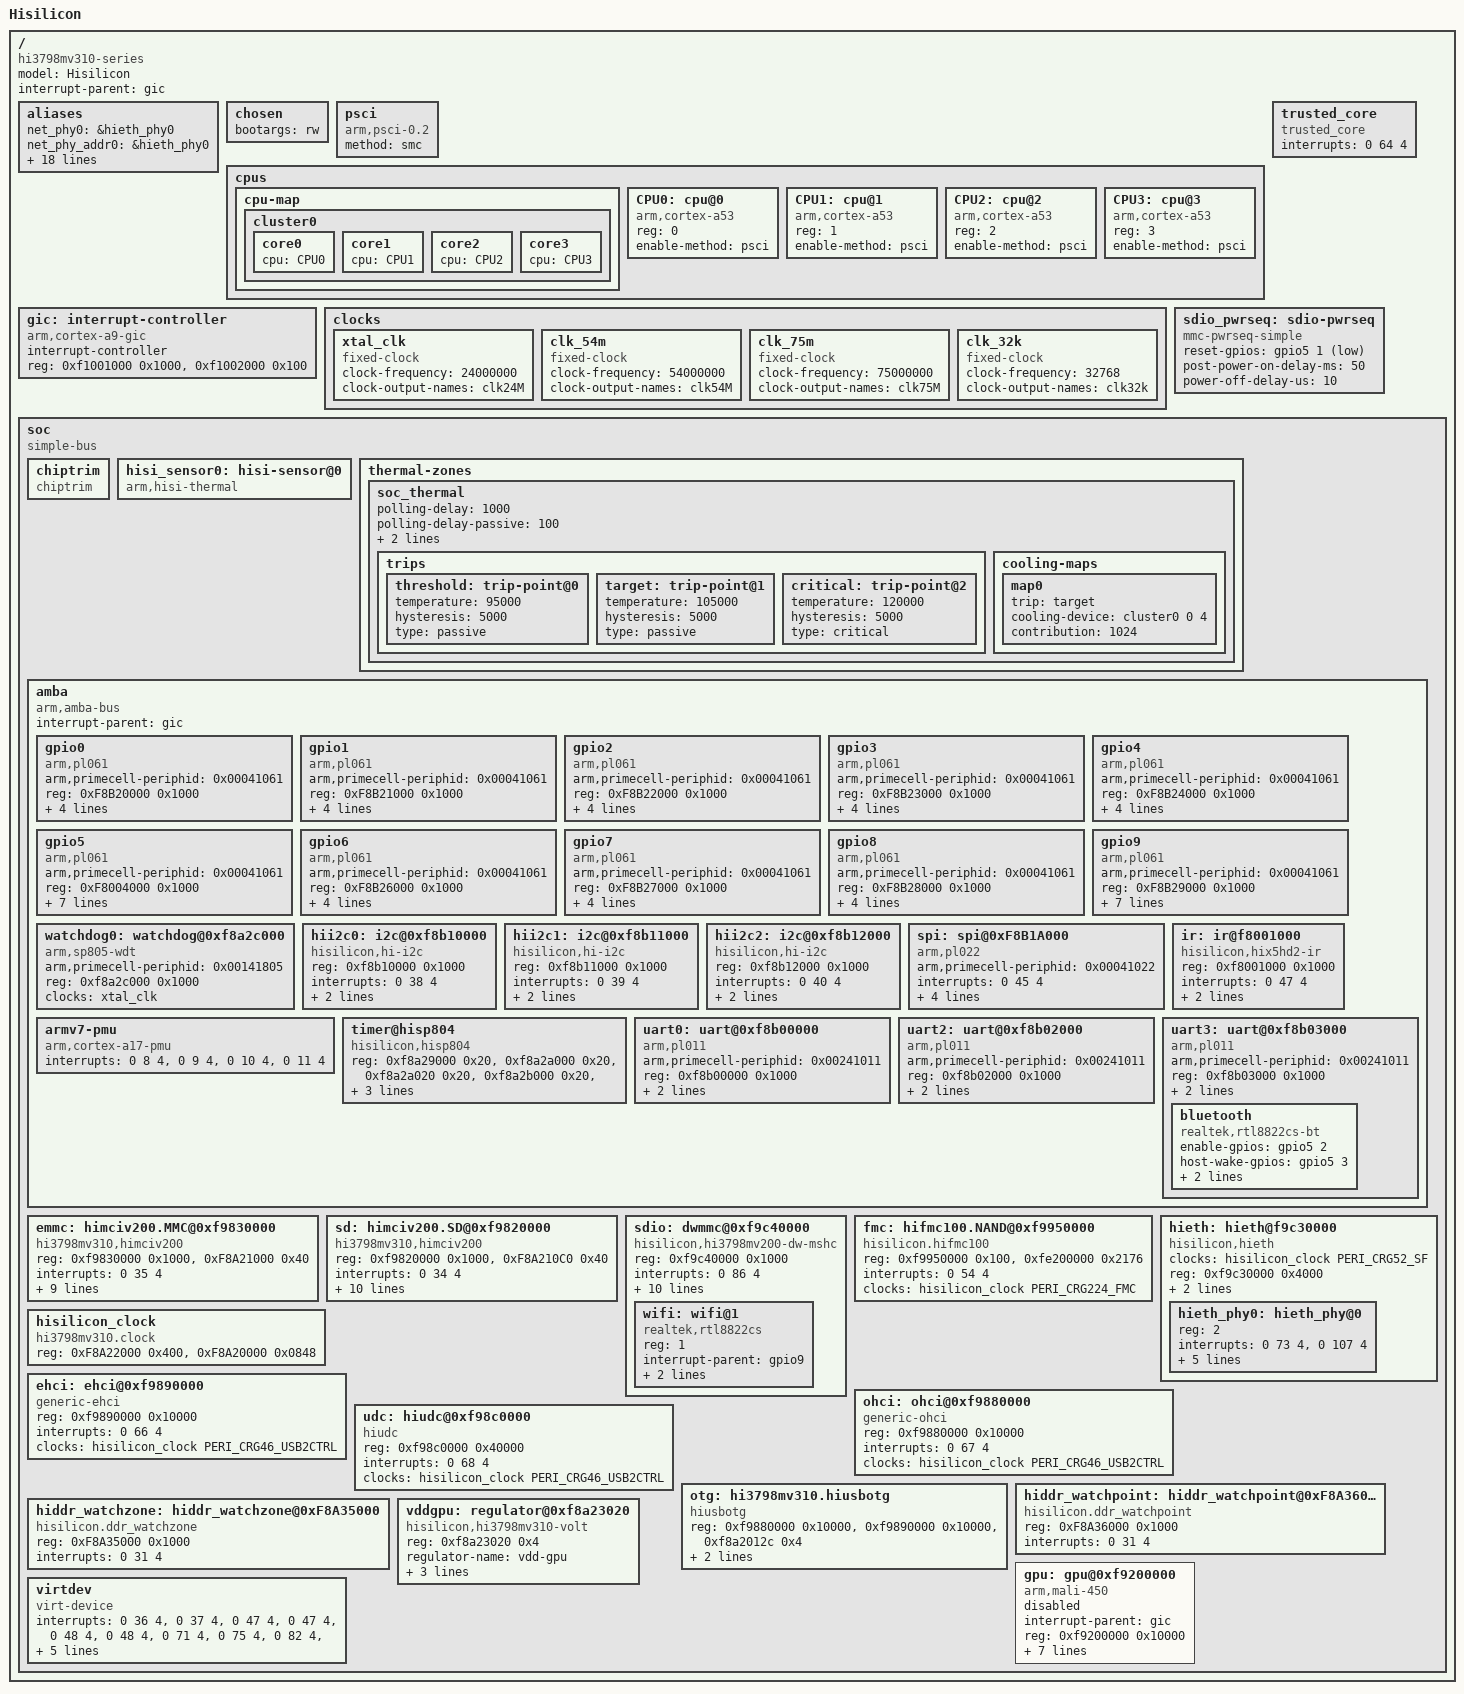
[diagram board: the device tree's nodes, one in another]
/dts-v1/;

#include <dt-bindings/clock/hi3798mv310-clock.h>
#include <dt-bindings/gpio/gpio.h>
#include <dt-bindings/interrupt-controller/irq.h>
#include <dt-bindings/interrupt-controller/arm-gic.h>

/ {
	model = "Hisilicon";
	compatible = "hi3798mv310-series";
	#address-cells = <1>;
	#size-cells = <1>;
	interrupt-parent = <&gic>;

	aliases {
		net_phy0 = &hieth_phy0;
		net_phy_addr0 = &hieth_phy0;
		emmc = &emmc;
		sd   = &sd;
		sdio = &sdio;
		ohci0= &ohci;
		ehci0= &ehci;
		uart0= &uart0;
		uart2= &uart2;
		uart3= &uart3;
		fmc  = &fmc;
		udc  = &udc;
		otg  = &otg;
		i2c0=&hii2c0;
		i2c1=&hii2c1;
		i2c2=&hii2c2;
		spi0=&spi;
		chiptrim=&chiptrim;
		wlan0 = &wifi;
		bluetooth0 = &bluetooth;
	};

	chosen {
		bootargs = "rw";
	};

	psci {
		compatible = "arm,psci-0.2";
		method = "smc";
	};

	cpus {
		#address-cells = <1>;
		#size-cells = <0>;
		#cooling-cells = <2>;

		cpu-map {
			cluster0: cluster0 {
				core0 { cpu = <&CPU0>; };
				core1 { cpu = <&CPU1>; };
				core2 { cpu = <&CPU2>; };
				core3 { cpu = <&CPU3>; };
			};
		};

		CPU0: cpu@0 {
			compatible = "arm,cortex-a53";
			device_type = "cpu";
			reg = <0>;
			enable-method = "psci";
		};
		CPU1: cpu@1 {
			compatible = "arm,cortex-a53";
			device_type = "cpu";
			reg = <1>;
			enable-method = "psci";
		};
		CPU2: cpu@2 {
			compatible = "arm,cortex-a53";
			device_type = "cpu";
			reg = <2>;
			enable-method = "psci";
		};
		CPU3: cpu@3 {
			compatible = "arm,cortex-a53";
			device_type = "cpu";
			reg = <3>;
			enable-method = "psci";
		};
	};

	gic: interrupt-controller {
		compatible = "arm,cortex-a9-gic";
		#interrupt-cells = <3>;
		#address-cells = <0>;
		interrupt-controller;
		reg = <0xf1001000 0x1000>, <0xf1002000 0x100>;
	};

	/* 固定时钟 */
	clocks {
		xtal_clk: xtal_clk {
			compatible = "fixed-clock";
			#clock-cells = <0>;
			clock-frequency = <24000000>;
			clock-output-names = "clk24M";
		};

		clk_54m: clk_54m{
			compatible = "fixed-clock";
			#clock-cells = <0>;
			clock-frequency = <54000000>;
			clock-output-names = "clk54M";
		};

		clk_75m: clk_75m{
			compatible = "fixed-clock";
			#clock-cells = <0>;
			clock-frequency = <75000000>;
			clock-output-names = "clk75M";
		};

		/* 6222B-SRC 低功耗时钟 - 引脚31 LPO, 32.768KHz */
		clk_32k: clk_32k {
			compatible = "fixed-clock";
			#clock-cells = <0>;
			clock-frequency = <32768>;
			clock-output-names = "clk32k";
		};
	};

	trusted_core {
		compatible = "trusted_core";
		interrupts = <0 64 4>;
	};

	/* 6222B-SRC WiFi 模块电源序列 - 控制 WL_REG_ON (gpio5_1) */
	sdio_pwrseq: sdio-pwrseq {
		compatible = "mmc-pwrseq-simple";
		/* WL_REG_ON - 引脚15, 高电平开启, 低电平关闭 */
		reset-gpios = <&gpio5 1 GPIO_ACTIVE_LOW>;
		/* 数据手册 Tchip Ready: 0-10ms, TSDIO Ready: 12ms, 取50ms确保稳定 */
		post-power-on-delay-ms = <50>;
		power-off-delay-us = <10>;
		status = "okay";
	};

	soc {
		#address-cells = <1>;
		#size-cells = <1>;
		compatible = "simple-bus";
		device_type = "soc";
		ranges = <0x0 0x0 0xffffffff>;

		chiptrim: chiptrim {
			compatible = "chiptrim";
		};

		hisi_sensor0: hisi-sensor@0 {
			compatible = "arm,hisi-thermal";
			#thermal-sensor-cells = <1>;
		};

		thermal-zones {
			soc_thermal {
				polling-delay = <1000>;
				polling-delay-passive = <100>;
				sustainable-power = <2500>;
				thermal-sensors = <&hisi_sensor0 0>;

				trips {
					threshold: trip-point@0 {
						temperature = <95000>;
						hysteresis = <5000>;
						type = "passive";
					};
					target: trip-point@1 {
						temperature = <105000>;
						hysteresis = <5000>;
						type = "passive";
					};
					critical: trip-point@2 {
						temperature = <120000>;
						hysteresis = <5000>;
						type = "critical";
					};
				};

				cooling-maps {
					map0 {
						trip = <&target>;
						cooling-device = <&cluster0 0 4>;
						contribution = <1024>;
					};
				};
			};
		};

		amba {
			compatible = "arm,amba-bus";
			#address-cells = <1>;
			#size-cells = <1>;
			interrupt-parent = <&gic>;
			ranges;

			/* GPIO 控制器 - 保持不变 */
			gpio0: gpio0 {
				compatible = "arm,pl061", "arm,primecell";
				arm,primecell-periphid = <0x00041061>;
				reg = <0xF8B20000 0x1000>;
				interrupts = <0 108 0x4>;
				gpio-controller;
				#gpio-cells = <2>;
				interrupt-controller;
				#interrupt-cells = <2>;
				clocks = <&xtal_clk>;
				clock-names = "apb_pclk";
			};

			gpio1: gpio1 {
				compatible = "arm,pl061", "arm,primecell";
				arm,primecell-periphid = <0x00041061>;
				reg = <0xF8B21000 0x1000>;
				interrupts = <0 109 4>;
				gpio-controller;
				#gpio-cells = <2>;
				interrupt-controller;
				#interrupt-cells = <2>;
				clocks = <&xtal_clk>;
				clock-names = "apb_pclk";
			};

			gpio2: gpio2 {
				compatible = "arm,pl061", "arm,primecell";
				arm,primecell-periphid = <0x00041061>;
				reg = <0xF8B22000 0x1000>;
				interrupts = <0 110 4>;
				gpio-controller;
				#gpio-cells = <2>;
				interrupt-controller;
				#interrupt-cells = <2>;
				clocks = <&xtal_clk>;
				clock-names = "apb_pclk";
			};

			gpio3: gpio3 {
				compatible = "arm,pl061", "arm,primecell";
				arm,primecell-periphid = <0x00041061>;
				reg = <0xF8B23000 0x1000>;
				interrupts = <0 111 4>;
				gpio-controller;
				#gpio-cells = <2>;
				interrupt-controller;
				#interrupt-cells = <2>;
				clocks = <&xtal_clk>;
				clock-names = "apb_pclk";
			};

			gpio4: gpio4 {
				compatible = "arm,pl061", "arm,primecell";
				arm,primecell-periphid = <0x00041061>;
				reg = <0xF8B24000 0x1000>;
				interrupts = <0 112 4>;
				gpio-controller;
				#gpio-cells = <2>;
				interrupt-controller;
				#interrupt-cells = <2>;
				clocks = <&xtal_clk>;
				clock-names = "apb_pclk";
			};

			gpio5: gpio5 {
				compatible = "arm,pl061", "arm,primecell";
				arm,primecell-periphid = <0x00041061>;
				reg = <0xF8004000 0x1000>;
				interrupts = <0 113 0>;
				gpio-controller;
				#gpio-cells = <2>;
				interrupt-controller;
				#interrupt-cells = <2>;
				clocks = <&xtal_clk>;
				clock-names = "apb_pclk";
			};

			gpio6: gpio6 {
				compatible = "arm,pl061", "arm,primecell";
				arm,primecell-periphid = <0x00041061>;
				reg = <0xF8B26000 0x1000>;
				interrupts = <0 114 4>;
				gpio-controller;
				#gpio-cells = <2>;
				interrupt-controller;
				#interrupt-cells = <2>;
				clocks = <&xtal_clk>;
				clock-names = "apb_pclk";
			};

			gpio7: gpio7 {
				compatible = "arm,pl061", "arm,primecell";
				arm,primecell-periphid = <0x00041061>;
				reg = <0xF8B27000 0x1000>;
				interrupts = <0 115 4>;
				gpio-controller;
				#gpio-cells = <2>;
				interrupt-controller;
				#interrupt-cells = <2>;
				clocks = <&xtal_clk>;
				clock-names = "apb_pclk";
			};

			gpio8: gpio8 {
				compatible = "arm,pl061", "arm,primecell";
				arm,primecell-periphid = <0x00041061>;
				reg = <0xF8B28000 0x1000>;
				interrupts = <0 116 4>;
				gpio-controller;
				#gpio-cells = <2>;
				interrupt-controller;
				#interrupt-cells = <2>;
				clocks = <&xtal_clk>;
				clock-names = "apb_pclk";
			};

			gpio9: gpio9 {
				compatible = "arm,pl061", "arm,primecell";
				arm,primecell-periphid = <0x00041061>;
				reg = <0xF8B29000 0x1000>;
				interrupts = <0 117 4>;
				gpio-controller;
				#gpio-cells = <2>;
				interrupt-controller;
				#interrupt-cells = <2>;
				clocks = <&xtal_clk>;
				clock-names = "apb_pclk";
			};

			watchdog0: watchdog@0xf8a2c000 {
				compatible = "arm,sp805-wdt", "arm,primecell";
				arm,primecell-periphid = <0x00141805>;
				reg = <0xf8a2c000 0x1000>;
				clocks = <&xtal_clk>;
				clock-names = "apb_pclk";
			};

			hii2c0:i2c@0xf8b10000 {
				compatible = "hisilicon,hi-i2c";
				reg = <0xf8b10000 0x1000>;
				interrupts = <0 38 4>;
				clock-frequency = <400000>;
				clocks = <&hisilicon_clock HII2C_I2C0_CLK>;
				clock-names = "apb_pclk";
				#address-cells = <1>;
				#size-cells = <0>;
			};

			hii2c1:i2c@0xf8b11000 {
				compatible = "hisilicon,hi-i2c";
				reg = <0xf8b11000 0x1000>;
				interrupts = <0 39 4>;
				clock-frequency = <400000>;
				clocks = <&hisilicon_clock HII2C_I2C1_CLK>;
				clock-names = "apb_pclk";
				#address-cells = <1>;
				#size-cells = <0>;
			};

			hii2c2:i2c@0xf8b12000 {
				compatible = "hisilicon,hi-i2c";
				reg = <0xf8b12000 0x1000>;
				interrupts = <0 40 4>;
				clock-frequency = <400000>;
				clocks = <&hisilicon_clock HII2C_I2C2_CLK>;
				clock-names = "apb_pclk";
				#address-cells = <1>;
				#size-cells = <0>;
			};

			spi:spi@0xF8B1A000 {
				compatible = "arm,pl022", "arm,primecell";
				arm,primecell-periphid = <0x00041022>;
				interrupts = <0 45 4>;
				reg = <0xF8B1A000 0x1000>;
				num-cs = <2>;
				#address-cells = <1>;
				#size-cells = <0>;
				clocks = <&hisilicon_clock PERI_CRG28_SSP>;
				clock-names = "apb_pclk";
				pl022,rt;
			};

			ir: ir@f8001000 {
				compatible = "hisilicon,hix5hd2-ir";
				reg = <0xf8001000 0x1000>;
				interrupts = <0 47 4>;
				clocks = <&hisilicon_clock HIIR_CLK>;
				linux,rc-map-name = "rc-hisi";
			};

			armv7-pmu {
				compatible = "arm,cortex-a17-pmu";
				interrupts = <0 8 4>, <0 9 4>, <0 10 4>, <0 11 4>;
			};

			timer@hisp804 {
				compatible = "hisilicon,hisp804";
				reg = <0xf8a29000 0x20>, <0xf8a2a000 0x20>,
				      <0xf8a2a020 0x20>, <0xf8a2b000 0x20>,
				      <0xf8a2b020 0x20>;
				interrupts = <0 26 4>, <0 59 4>, <0 27 4>, <0 60 4>;
				clocks = <&xtal_clk>;
				clock-names = "apb_pclk";
			};

			uart0: uart@0xf8b00000 {
				compatible = "arm,pl011", "arm,primecell";
				arm,primecell-periphid = <0x00241011>;
				reg = <0xf8b00000 0x1000>;
				interrupts = <0 49 4>;
				clocks = <&clk_75m>;
				clock-names = "apb_pclk";
				status = "okay";
			};

			uart2: uart@0xf8b02000 {
				compatible = "arm,pl011", "arm,primecell";
				arm,primecell-periphid = <0x00241011>;
				reg = <0xf8b02000 0x1000>;
				interrupts = <0 51 4>;
				clocks = <&clk_75m>;
				clock-names = "apb_pclk";
				status = "okay";
			};

			uart3: uart@0xf8b03000 {
				compatible = "arm,pl011", "arm,primecell";
				arm,primecell-periphid = <0x00241011>;
				reg = <0xf8b03000 0x1000>;
				interrupts = <0 52 4>;
				clocks = <&clk_75m>;
				clock-names = "apb_pclk";
				status = "okay";

				/* 6222B-SRC 蓝牙 HCI - 引脚40-43, 数据手册第7页: HCI UART up to 4Mbps */
				bluetooth: bluetooth {
					compatible = "realtek,rtl8822cs-bt";
					/* BT_REG_ON - 引脚38 */
					enable-gpios = <&gpio5 2 GPIO_ACTIVE_HIGH>;
					/* HOST_WAKE_BT - 引脚49 */
					host-wake-gpios = <&gpio5 3 GPIO_ACTIVE_HIGH>;
					/* BT_WAKE_HOST - 引脚50 */
					device-wake-gpios = <&gpio5 4 GPIO_ACTIVE_HIGH>;
					/* 最大速度 4Mbps */
					max-speed = <4000000>;
					status = "okay";
				};
			};
		};

		/* eMMC - 保持不变 */
		emmc: himciv200.MMC@0xf9830000 {
			compatible = "hi3798mv310,himciv200";
			reg = <0xf9830000 0x1000>, <0xF8A21000 0x40>;
			interrupts = <0 35 4>;
			clocks = <&hisilicon_clock PERI_CRG40_SDIO1>;
			clock-names = "clk";
			caps = <0xc0000847>;
			caps2 = <0x0>;
			max-frequency = <50000000>;
			bus-width = <8>;
			non-removable;
			cap-mmc-highspeed;
			mmc-hs200-1_8v;
			mmc-hs400-1_8v;
			status = "okay";
		};

		/* SD 卡槽 - 保持不变 */
		sd: himciv200.SD@0xf9820000 {
			compatible = "hi3798mv310,himciv200";
			reg = <0xf9820000 0x1000>, <0xF8A210C0 0x40>;
			interrupts = <0 34 4>;
			clocks = <&hisilicon_clock PERI_CRG39_SDIO0>;
			clock-names = "clk";
			ldo-addr = <0xf8a2011c>;
			ldo-shift = <0>;
			caps = <0x8007000f>;
			caps2 = <0x4000>;
			max-frequency = <50000000>;
			bus-width = <4>;
			cd-gpios = <&gpio5 0 0>;
			cd-inverted;
			cap-sd-highspeed;
			status = "okay";
		};

		/* ====================================================== */
		/* SDIO for 6222B-SRC WiFi/BT Combo Module                */
		/* 使用 dw_mmc 驱动 - 标准 DesignWare 控制器             */
		/* ====================================================== */
		sdio: dwmmc@0xf9c40000 {
			compatible = "hisilicon,hi3798mv200-dw-mshc", "snps,dw-mshc";
			reg = <0xf9c40000 0x1000>;
			interrupts = <0 86 4>;
			interrupt-names = "sdio_irq";

			/* dw_mmc 需要两个时钟：biu（总线接口）和 ciu（卡接口） */
			clocks = <&hisilicon_clock PERI_CRG163_SDIO2>, <&xtal_clk>;
			clock-names = "biu", "ciu";

			/* SDIO 配置 */
			bus-width = <4>;
			non-removable;
			cap-sd-highspeed;
			cap-sdio-irq;
			keep-power-in-suspend;
			enable-sdio-wakeup;
			max-frequency = <50000000>;

			/* 电源序列 - 控制 WL_REG_ON (gpio5_1) */
			mmc-pwrseq = <&sdio_pwrseq>;

			status = "okay";

			#address-cells = <1>;
			#size-cells = <0>;

			/* WiFi SDIO 设备 */
			wifi: wifi@1 {
				compatible = "realtek,rtl8822cs", "rtl8822bs", "sdio";
				reg = <1>;

				/* WL_WAKE_HOST - OOB中断 */
				interrupt-parent = <&gpio9>;
				interrupts = <0 IRQ_TYPE_EDGE_FALLING>;
				interrupt-names = "host-wake";

				/* SD_RESET - 可选 */
				reset-gpios = <&gpio5 5 GPIO_ACTIVE_LOW>;

				status = "okay";
			};
		};

		fmc: hifmc100.NAND@0xf9950000 {
			compatible = "hisilicon.hifmc100";
			reg = <0xf9950000 0x100>, <0xfe200000 0x2176>;
			interrupts = <0 54 4>;
			clocks = <&hisilicon_clock PERI_CRG224_FMC>;
			clock-names = "clk";
			status = "okay";
		};

		hisilicon_clock: hisilicon_clock {
			compatible = "hi3798mv310.clock", "hisilicon,clock-reset";
			reg = <0xF8A22000 0x400>, <0xF8A20000 0x0848>;
			#clock-cells = <1>;
			#reset-cells = <2>;
		};

		hieth: hieth@f9c30000 {
			compatible = "hisilicon,hieth";
			clocks = <&hisilicon_clock PERI_CRG52_SF>;
			clock-names = "clk";
			reg = <0xf9c30000 0x4000>;
			interrupts = <0 72 4>;
			phy-handle = <&hieth_phy0>;
			#address-cells = <1>;
			#size-cells = <0>;
			status = "okay";

			hieth_phy0: hieth_phy@0 {
				reg = <2>;
				interrupts = <0 73 4>, <0 107 4>;
				mac-address = [00 00 00 00 00 00];
				phy-mode = "mii";
				phy-gpio-base = <0>;
				phy-gpio-bit = <0>;
				internal-phy;
			};
		};

		ehci: ehci@0xf9890000 {
			compatible = "generic-ehci";
			reg = <0xf9890000 0x10000>;
			interrupts = <0 66 4>;
			clocks = <&hisilicon_clock PERI_CRG46_USB2CTRL>;
			clock-names = "clk";
			status = "okay";
		};

		ohci: ohci@0xf9880000 {
			compatible = "generic-ohci";
			reg = <0xf9880000 0x10000>;
			interrupts = <0 67 4>;
			clocks = <&hisilicon_clock PERI_CRG46_USB2CTRL>;
			clock-names = "clk";
			status = "okay";
		};

		udc: hiudc@0xf98c0000 {
			compatible = "hiudc";
			reg = <0xf98c0000 0x40000>;
			interrupts = <0 68 4>;
			clocks = <&hisilicon_clock PERI_CRG46_USB2CTRL>;
			clock-names = "clk";
			status = "okay";
		};

		otg: hi3798mv310.hiusbotg {
			compatible = "hiusbotg";
			reg = <0xf9880000 0x10000>, <0xf9890000 0x10000>, <0xf8a2012c 0x4>;
			host_time = <1500 4>;
			device_time = <1000 4>;
			status = "okay";
		};

		hiddr_watchpoint: hiddr_watchpoint@0xF8A36000 {
			compatible = "hisilicon.ddr_watchpoint";
			reg = <0xF8A36000 0x1000>;
			interrupts = <0 31 4>;
		};

		hiddr_watchzone: hiddr_watchzone@0xF8A35000 {
			compatible = "hisilicon.ddr_watchzone";
			reg = <0xF8A35000 0x1000>;
			interrupts = <0 31 4>;
		};

		vddgpu: regulator@0xf8a23020 {
			compatible = "hisilicon,hi3798mv310-volt";
			reg = <0xf8a23020 0x4>;
			reg-names = "Hisilicon GPU Regulator";
			regulator-name = "vdd-gpu";
			regulator-min-microvolt = <700000>;
			regulator-max-microvolt = <1250000>;
			regulator-always-on;
			status = "okay";
		};

		gpu: gpu@0xf9200000 {
			compatible = "arm,mali-450", "arm,mali-utgard";
			interrupt-parent = <&gic>;
			reg = <0xf9200000 0x10000>;
			interrupts = <0 94 4>, <0 94 4>, <0 94 4>, <0 94 4>,
				     <0 94 4>, <0 94 4>, <0 94 4>, <0 94 4>;
			interrupt-names = "IRQGP", "IRQGPMMU", "IRQPP0", "IRQPPMMU0",
					  "IRQPP1", "IRQPPMMU1", "IRQPMU", "IRQPP";
			pmu_domain_config = <0x1 0x2 0x2 0x0 0x0 0x0 0x0 0x0 0x0 0x1 0x2 0x0>;
			pmu_switch_delay = <0x1ff>;
			#cooling-cells = <2>;
			clocks = <&hisilicon_clock PERI_CRG73_GPU_LP>;
			clock-names = "clk_mali";
			mali-supply = <&vddgpu>;
			status = "disabled";
		};

		virtdev {
			compatible = "virt-device";
			interrupts = <0 36 4>, <0 37 4>, <0 47 4>, <0 47 4>,
				     <0 48 4>, <0 48 4>, <0 71 4>, <0 75 4>,
				     <0 82 4>, <0 84 4>, <0 88 4>, <0 90 4>,
				     <0 91 4>, <0 91 4>, <0 93 4>, <0 94 4>,
				     <0 95 4>, <0 96 4>, <0 97 4>, <0 101 4>,
				     <0 102 4>, <0 104 4>, <0 105 4>, <0 106 4>,
				     <0 126 4>, <0 146 4>, <0 147 4>, <0 148 4>,
				     <0 149 4>, <0 150 4>, <0 157 4>;
			interrupt-names = "sci0", "sci1", "ir_std", "ir_s2",
					  "keyled_ct1642", "keyled_std", "gsf0", "multicipher",
					  "dmx", "aiao", "hdmi", "vdp",
					  "tde", "gfx2d", "vpss0", "gpu",
					  "vdec_vdh", "png", "jpeg", "venc",
					  "jpge", "vdec_scd", "vdec_vdh_safe", "vdec_scd_safe",
					  "cipher", "SecInvokeirq", "hdmi_cec", "mmu_vdh_safe",
					  "mmu_vdh", "pastc", "sm2";
		};
	};
};

/* GPIO 引脚功能定义 - 基于 6222B-SRC 数据手册 */
&gpio5 {
	gpio-line-names = "SD_CD",      /* 引脚0 - SD卡检测 */
			  "WL_REG_ON",   /* 引脚1 - 6222B-SRC 引脚15, 高电平亮绿灯 */
			  "BT_REG_ON",   /* 引脚2 - 6222B-SRC 引脚38 */
			  "HOST_WAKE_BT", /* 引脚3 - 6222B-SRC 引脚49 */
			  "BT_WAKE_HOST", /* 引脚4 - 6222B-SRC 引脚50 */
			  "SD_RESET",    /* 引脚5 - 6222B-SRC 引脚44 */
			  "GPIO5_6",
			  "GPIO5_7";
};

&gpio9 {
	gpio-line-names = "WL_WAKE_HOST", /* 引脚0 - 6222B-SRC 引脚16/24, OOB中断 */
			  "GPIO9_1",
			  "GPIO9_2",
			  "GPIO9_3",
			  "GPIO9_4",
			  "GPIO9_5",
			  "GPIO9_6",
			  "GPIO9_7";
};
